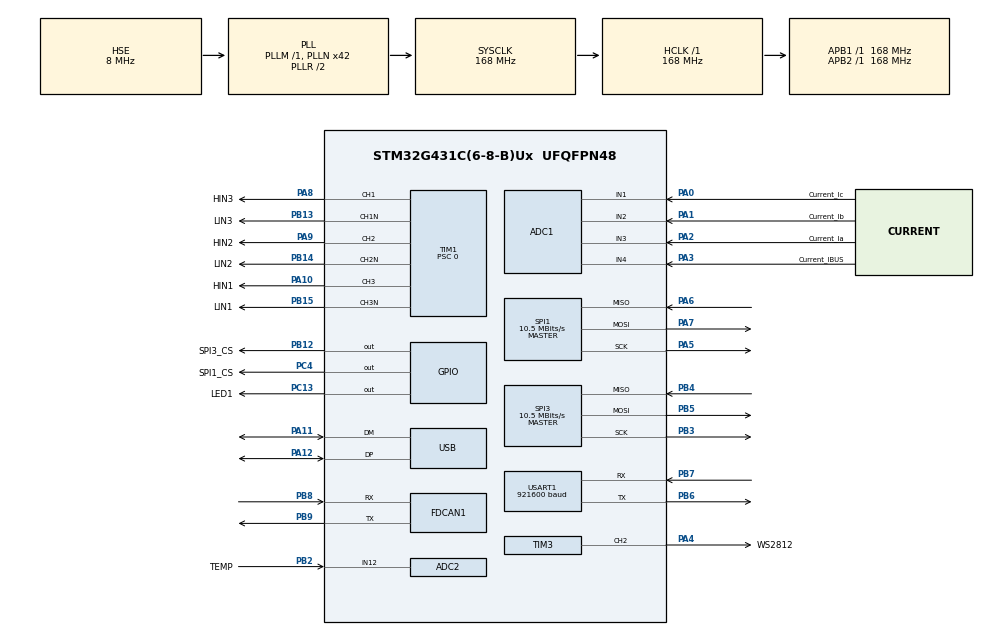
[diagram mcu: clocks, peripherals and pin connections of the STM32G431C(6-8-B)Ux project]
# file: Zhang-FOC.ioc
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ADC1.ClockPrescaler=ADC_CLOCK_SYNC_PCLK_DIV4
ADC1.ContinuousConvMode=DISABLE
ADC1.DMAContinuousRequests=DISABLE
ADC1.EOCSelection=ADC_EOC_SINGLE_CONV
ADC1.EnableAnalogWatchDog1=false
ADC1.EnableInjectedConversion=ENABLE
ADC1.EnableRegularConversion=DISABLE
ADC1.ExternalTrigInjecConv=ADC_EXTERNALTRIGINJEC_T1_CC4
ADC1.ExternalTrigInjecConvEdge=ADC_EXTERNALTRIGINJECCONV_EDGE_RISING
ADC1.InjNumberOfConversion=4
ADC1.InjectedChannel-4\#ChannelInjectedConversion=ADC_CHANNEL_1
ADC1.InjectedChannel-5\#ChannelInjectedConversion=ADC_CHANNEL_2
ADC1.InjectedChannel-6\#ChannelInjectedConversion=ADC_CHANNEL_3
ADC1.InjectedChannel-7\#ChannelInjectedConversion=ADC_CHANNEL_4
ADC1.InjectedOffsetNumber-4\#ChannelInjectedConversion=ADC_OFFSET_NONE
ADC1.InjectedOffsetNumber-5\#ChannelInjectedConversion=ADC_OFFSET_NONE
ADC1.InjectedOffsetNumber-6\#ChannelInjectedConversion=ADC_OFFSET_NONE
ADC1.InjectedOffsetNumber-7\#ChannelInjectedConversion=ADC_OFFSET_NONE
ADC1.InjectedRank-4\#ChannelInjectedConversion=1
ADC1.InjectedRank-5\#ChannelInjectedConversion=2
ADC1.InjectedRank-6\#ChannelInjectedConversion=3
ADC1.InjectedRank-7\#ChannelInjectedConversion=4
ADC1.InjectedSamplingTime-4\#ChannelInjectedConversion=ADC_SAMPLETIME_6CYCLES_5
ADC1.InjectedSamplingTime-5\#ChannelInjectedConversion=ADC_SAMPLETIME_6CYCLES_5
ADC1.InjectedSamplingTime-6\#ChannelInjectedConversion=ADC_SAMPLETIME_6CYCLES_5
ADC1.InjectedSamplingTime-7\#ChannelInjectedConversion=ADC_SAMPLETIME_6CYCLES_5
ADC1.master=1
ADC2.Channel-0\#ChannelRegularConversion=ADC_CHANNEL_12
ADC2.ContinuousConvMode=ENABLE
ADC2.DMAContinuousRequests=ENABLE
ADC2.GainCompensation=0
ADC2.NbrOfConversionFlag=1
ADC2.OffsetNumber-0\#ChannelRegularConversion=ADC_OFFSET_NONE
ADC2.Rank-0\#ChannelRegularConversion=1
ADC2.SamplingTime-0\#ChannelRegularConversion=ADC_SAMPLETIME_47CYCLES_5
Dma.ADC2.1.Direction=DMA_PERIPH_TO_MEMORY
Dma.ADC2.1.EventEnable=DISABLE
Dma.ADC2.1.Instance=DMA1_Channel2
Dma.ADC2.1.MemDataAlignment=DMA_MDATAALIGN_HALFWORD
Dma.ADC2.1.MemInc=DMA_MINC_ENABLE
Dma.ADC2.1.Mode=DMA_CIRCULAR
Dma.ADC2.1.PeriphDataAlignment=DMA_PDATAALIGN_HALFWORD
Dma.ADC2.1.PeriphInc=DMA_PINC_DISABLE
Dma.ADC2.1.Polarity=HAL_DMAMUX_REQ_GEN_RISING
Dma.ADC2.1.Priority=DMA_PRIORITY_MEDIUM
Dma.ADC2.1.RequestNumber=1
Dma.ADC2.1.SignalID=NONE
Dma.ADC2.1.SyncEnable=DISABLE
Dma.ADC2.1.SyncPolarity=HAL_DMAMUX_SYNC_NO_EVENT
Dma.ADC2.1.SyncRequestNumber=1
Dma.ADC2.1.SyncSignalID=NONE
Dma.Request0=TIM3_CH2
Dma.Request1=ADC2
Dma.Request2=USART1_RX
Dma.Request3=USART1_TX
Dma.TIM3_CH2.0.Direction=DMA_MEMORY_TO_PERIPH
Dma.TIM3_CH2.0.EventEnable=DISABLE
Dma.TIM3_CH2.0.Instance=DMA1_Channel1
Dma.TIM3_CH2.0.MemDataAlignment=DMA_MDATAALIGN_WORD
Dma.TIM3_CH2.0.MemInc=DMA_MINC_ENABLE
Dma.TIM3_CH2.0.Mode=DMA_NORMAL
Dma.TIM3_CH2.0.PeriphDataAlignment=DMA_PDATAALIGN_WORD
Dma.TIM3_CH2.0.PeriphInc=DMA_PINC_DISABLE
Dma.TIM3_CH2.0.Polarity=HAL_DMAMUX_REQ_GEN_RISING
Dma.TIM3_CH2.0.Priority=DMA_PRIORITY_MEDIUM
Dma.TIM3_CH2.0.RequestNumber=1
Dma.TIM3_CH2.0.SignalID=NONE
Dma.TIM3_CH2.0.SyncEnable=DISABLE
Dma.TIM3_CH2.0.SyncPolarity=HAL_DMAMUX_SYNC_NO_EVENT
Dma.TIM3_CH2.0.SyncRequestNumber=1
Dma.TIM3_CH2.0.SyncSignalID=NONE
Dma.USART1_RX.2.Direction=DMA_PERIPH_TO_MEMORY
Dma.USART1_RX.2.EventEnable=DISABLE
Dma.USART1_RX.2.Instance=DMA1_Channel3
Dma.USART1_RX.2.MemDataAlignment=DMA_MDATAALIGN_BYTE
Dma.USART1_RX.2.MemInc=DMA_MINC_ENABLE
Dma.USART1_RX.2.Mode=DMA_NORMAL
Dma.USART1_RX.2.PeriphDataAlignment=DMA_PDATAALIGN_BYTE
Dma.USART1_RX.2.PeriphInc=DMA_PINC_DISABLE
Dma.USART1_RX.2.Polarity=HAL_DMAMUX_REQ_GEN_RISING
Dma.USART1_RX.2.Priority=DMA_PRIORITY_HIGH
Dma.USART1_RX.2.RequestNumber=1
Dma.USART1_RX.2.SignalID=NONE
Dma.USART1_RX.2.SyncEnable=DISABLE
Dma.USART1_RX.2.SyncPolarity=HAL_DMAMUX_SYNC_NO_EVENT
Dma.USART1_RX.2.SyncRequestNumber=1
Dma.USART1_RX.2.SyncSignalID=NONE
Dma.USART1_TX.3.Direction=DMA_MEMORY_TO_PERIPH
Dma.USART1_TX.3.EventEnable=DISABLE
Dma.USART1_TX.3.Instance=DMA1_Channel4
Dma.USART1_TX.3.MemDataAlignment=DMA_MDATAALIGN_BYTE
Dma.USART1_TX.3.MemInc=DMA_MINC_ENABLE
Dma.USART1_TX.3.Mode=DMA_NORMAL
Dma.USART1_TX.3.PeriphDataAlignment=DMA_PDATAALIGN_BYTE
Dma.USART1_TX.3.PeriphInc=DMA_PINC_DISABLE
Dma.USART1_TX.3.Polarity=HAL_DMAMUX_REQ_GEN_RISING
Dma.USART1_TX.3.Priority=DMA_PRIORITY_HIGH
Dma.USART1_TX.3.RequestNumber=1
Dma.USART1_TX.3.SignalID=NONE
Dma.USART1_TX.3.SyncEnable=DISABLE
Dma.USART1_TX.3.SyncPolarity=HAL_DMAMUX_SYNC_NO_EVENT
Dma.USART1_TX.3.SyncRequestNumber=1
Dma.USART1_TX.3.SyncSignalID=NONE
FDCAN1.AutoRetransmission=ENABLE
FDCAN1.CalculateBaudRateNominal=1000000
FDCAN1.CalculateTimeBitNominal=1000
FDCAN1.CalculateTimeQuantumNominal=35.714285714285715
FDCAN1.ClockDivider=FDCAN_CLOCK_DIV1
FDCAN1.DataPrescaler=6
FDCAN1.DataSyncJumpWidth=7
FDCAN1.DataTimeSeg1=20
FDCAN1.DataTimeSeg2=7
FDCAN1.NominalPrescaler=6
FDCAN1.NominalSyncJumpWidth=7
FDCAN1.NominalTimeSeg1=20
FDCAN1.NominalTimeSeg2=7
FDCAN1.ProtocolException=ENABLE
FDCAN1.StdFiltersNbr=1
FREERTOS.INCLUDE_uxTaskGetStackHighWaterMark=1
FREERTOS.INCLUDE_vTaskDelayUntil=1
FREERTOS.MEMORY_ALLOCATION=2
FREERTOS.Tasks01=defaultTask,0,128,StartDefaultTask,As weak,NULL,Dynamic,NULL,NULL;guardtask,0,128,StartGuardTask,As weak,NULL,Dynamic,NULL,NULL;customtask,1,400,StartCustomTask,As weak,NULL,Dynamic,NULL,NULL
FREERTOS.configCHECK_FOR_STACK_OVERFLOW=1
FREERTOS.configTOTAL_HEAP_SIZE=3000
FREERTOS.configUSE_APPLICATION_TASK_TAG=0
FREERTOS.configUSE_IDLE_HOOK=1
Mcu.Family=STM32G4
Mcu.Name=STM32G431C(6-8-B)Ux
Mcu.Package=UFQFPN48
Mcu.UserConstants=MCPWM_CLOCK_HZ,168000000;MCPWM_DEADTIME_CLOCKS,20;MCPWM_TGRO_TIME,MCPWM_PERIOD_CLOCKS-10;MCPWM_RCR,0;MCPWM_FREQ,20000;MCPWM_PERIOD_CLOCKS,MCPWM_CLOCK_HZ/2/MCPWM_FREQ
NVIC.ADC1_2_IRQn=true\:5\:0\:true\:false\:true\:true\:true\:true\:true
NVIC.DMA1_Channel1_IRQn=true\:5\:0\:false\:false\:true\:true\:false\:true\:true
NVIC.DMA1_Channel2_IRQn=true\:5\:0\:false\:false\:true\:true\:false\:true\:true
NVIC.DMA1_Channel3_IRQn=true\:5\:0\:false\:false\:true\:true\:false\:true\:true
NVIC.DMA1_Channel4_IRQn=true\:5\:0\:false\:false\:true\:true\:false\:true\:true
NVIC.FDCAN1_IT0_IRQn=true\:6\:0\:true\:false\:true\:true\:true\:true\:true
NVIC.FDCAN1_IT1_IRQn=true\:6\:0\:true\:false\:true\:true\:true\:true\:true
NVIC.PriorityGroup=NVIC_PRIORITYGROUP_4
NVIC.TIM1_TRG_COM_TIM17_IRQn=true\:15\:0\:false\:false\:true\:false\:false\:true\:true
NVIC.TimeBase=TIM1_TRG_COM_TIM17_IRQn
NVIC.TimeBaseIP=TIM17
NVIC.USART1_IRQn=true\:7\:0\:true\:false\:true\:true\:true\:true\:true
NVIC.USB_LP_IRQn=true\:5\:0\:false\:false\:true\:true\:false\:true\:true
PA0.GPIO_Label=Current_Ic
PA0.Mode=IN1-Single-Ended
PA0.Signal=ADC1_IN1
PA1.GPIO_Label=Current_Ib
PA1.Mode=IN2-Single-Ended
PA1.Signal=ADC1_IN2
PA10.GPIO_Label=HIN1
PA10.GPIO_Speed=GPIO_SPEED_FREQ_VERY_HIGH
PA10.Signal=S_TIM1_CH3
PA11.Mode=Device
PA11.Signal=USB_DM
PA12.Mode=Device
PA12.Signal=USB_DP
PA13.Mode=Serial_Wire
PA13.Signal=SYS_JTMS-SWDIO
PA14.Mode=Serial_Wire
PA14.Signal=SYS_JTCK-SWCLK
PA2.GPIO_Label=Current_Ia
PA2.Mode=IN3-Single-Ended
PA2.Signal=ADC1_IN3
PA3.GPIO_Label=Current_IBUS
PA3.Mode=IN4-Single-Ended
PA3.Signal=ADC1_IN4
PA4.GPIO_Label=WS2812
PA4.Signal=S_TIM3_CH2
PA5.GPIO_Speed=GPIO_SPEED_FREQ_VERY_HIGH
PA5.Mode=Full_Duplex_Master
PA5.Signal=SPI1_SCK
PA6.GPIO_Speed=GPIO_SPEED_FREQ_VERY_HIGH
PA6.Mode=Full_Duplex_Master
PA6.Signal=SPI1_MISO
PA7.GPIO_Speed=GPIO_SPEED_FREQ_VERY_HIGH
PA7.Mode=Full_Duplex_Master
PA7.Signal=SPI1_MOSI
PA8.GPIO_Label=HIN3
PA8.GPIO_Speed=GPIO_SPEED_FREQ_VERY_HIGH
PA8.Signal=S_TIM1_CH1
PA9.GPIO_Label=HIN2
PA9.GPIO_Speed=GPIO_SPEED_FREQ_VERY_HIGH
PA9.Signal=S_TIM1_CH2
PB12.GPIO_Label=SPI3_CS
PB12.GPIO_Speed=GPIO_SPEED_FREQ_VERY_HIGH
PB12.Signal=GPIO_Output
PB13.GPIO_Label=LIN3
PB13.GPIO_Speed=GPIO_SPEED_FREQ_VERY_HIGH
PB13.Mode=PWM Generation1 CH1 CH1N
PB13.Signal=TIM1_CH1N
PB14.GPIO_Label=LIN2
PB14.GPIO_Speed=GPIO_SPEED_FREQ_VERY_HIGH
PB14.Mode=PWM Generation2 CH2 CH2N
PB14.Signal=TIM1_CH2N
PB15.GPIO_Label=LIN1
PB15.GPIO_Speed=GPIO_SPEED_FREQ_VERY_HIGH
PB15.Mode=PWM Generation3 CH3 CH3N
PB15.Signal=TIM1_CH3N
PB2.GPIO_Label=TEMP
PB2.Mode=IN12-Single-Ended
PB2.Signal=ADC2_IN12
PB3.GPIO_Speed=GPIO_SPEED_FREQ_VERY_HIGH
PB3.Mode=Full_Duplex_Master
PB3.Signal=SPI3_SCK
PB4.GPIO_Speed=GPIO_SPEED_FREQ_VERY_HIGH
PB4.Mode=Full_Duplex_Master
PB4.Signal=SPI3_MISO
PB5.GPIO_Speed=GPIO_SPEED_FREQ_VERY_HIGH
PB5.Mode=Full_Duplex_Master
PB5.Signal=SPI3_MOSI
PB6.GPIO_Speed=GPIO_SPEED_FREQ_VERY_HIGH
PB6.Mode=Asynchronous
PB6.Signal=USART1_TX
PB7.GPIO_Speed=GPIO_SPEED_FREQ_VERY_HIGH
PB7.Mode=Asynchronous
PB7.Signal=USART1_RX
PB8-BOOT0.GPIO_Speed=GPIO_SPEED_FREQ_VERY_HIGH
PB8-BOOT0.Mode=FDCAN_Activate
PB8-BOOT0.Signal=FDCAN1_RX
PB9.GPIO_Speed=GPIO_SPEED_FREQ_VERY_HIGH
PB9.Mode=FDCAN_Activate
PB9.Signal=FDCAN1_TX
PC13.GPIO_Label=LED1
PC13.Signal=GPIO_Output
PC4.GPIO_Label=SPI1_CS
PC4.GPIO_Speed=GPIO_SPEED_FREQ_VERY_HIGH
PC4.Signal=GPIO_Output
PF0-OSC_IN.Mode=HSE-External-Oscillator
PF0-OSC_IN.Signal=RCC_OSC_IN
PF1-OSC_OUT.Mode=HSE-External-Oscillator
PF1-OSC_OUT.Signal=RCC_OSC_OUT
ProjectManager.HeapSize=0x3000
ProjectManager.StackSize=0x1000
ProjectManager.TargetToolchain=MDK-ARM V5.32
RCC.ADC12CLockSelection=RCC_ADC12CLKSOURCE_PLL
RCC.ADC12Freq_Value=168000000
RCC.AHBFreq_Value=168000000
RCC.APB1Freq_Value=168000000
RCC.APB1TimFreq_Value=168000000
RCC.APB2Freq_Value=168000000
RCC.APB2TimFreq_Value=168000000
RCC.CK48CLockSelection=RCC_USBCLKSOURCE_HSI48
RCC.CortexFreq_Value=168000000
RCC.EXTERNAL_CLOCK_VALUE=12288000
RCC.FDCANCLockSelection=RCC_FDCANCLKSOURCE_PLL
RCC.HCLKFreq_Value=168000000
RCC.HSE_VALUE=8000000
RCC.HSI48_VALUE=48000000
RCC.HSI_VALUE=16000000
RCC.LSE_VALUE=32768
RCC.PLLN=42
RCC.PLLSourceVirtual=RCC_PLLSOURCE_HSE
RCC.SYSCLKFreq_VALUE=168000000
RCC.SYSCLKSource=RCC_SYSCLKSOURCE_PLLCLK
RCC.USBFreq_Value=48000000
RCC.VCOOutputFreq_Value=336000000
SH.S_TIM1_CH1.0=TIM1_CH1,PWM Generation1 CH1 CH1N
SH.S_TIM1_CH2.0=TIM1_CH2,PWM Generation2 CH2 CH2N
SH.S_TIM1_CH3.0=TIM1_CH3,PWM Generation3 CH3 CH3N
SH.S_TIM3_CH2.0=TIM3_CH2,PWM Generation2 CH2
SPI1.BaudRatePrescaler=SPI_BAUDRATEPRESCALER_16
SPI1.CLKPhase=SPI_PHASE_2EDGE
SPI1.CLKPolarity=SPI_POLARITY_HIGH
SPI1.CalculateBaudRate=10.5 MBits/s
SPI1.DataSize=SPI_DATASIZE_8BIT
SPI1.Direction=SPI_DIRECTION_2LINES
SPI1.Mode=SPI_MODE_MASTER
SPI1.VirtualType=VM_MASTER
SPI3.BaudRatePrescaler=SPI_BAUDRATEPRESCALER_16
SPI3.CLKPhase=SPI_PHASE_2EDGE
SPI3.CLKPolarity=SPI_POLARITY_HIGH
SPI3.CalculateBaudRate=10.5 MBits/s
SPI3.DataSize=SPI_DATASIZE_8BIT
SPI3.Direction=SPI_DIRECTION_2LINES
SPI3.Mode=SPI_MODE_MASTER
SPI3.VirtualType=VM_MASTER
STMicroelectronics.X-CUBE-ALGOBUILD.1.4.0.LibraryCcDSPOoLibraryJjDSPOoLibrary=true
TIM1.BreakFilter=0
TIM1.BreakState=TIM_BREAK_DISABLE
TIM1.Channel-PWM\ Generation1\ CH1\ CH1N=TIM_CHANNEL_1
TIM1.Channel-PWM\ Generation2\ CH2\ CH2N=TIM_CHANNEL_2
TIM1.Channel-PWM\ Generation3\ CH3\ CH3N=TIM_CHANNEL_3
TIM1.Channel-PWM\ Generation4\ No\ Output=TIM_CHANNEL_4
TIM1.ClockDivision=TIM_CLOCKDIVISION_DIV1
TIM1.CounterMode=TIM_COUNTERMODE_CENTERALIGNED1
TIM1.DeadTime=MCPWM_DEADTIME_CLOCKS
TIM1.LockLevel=TIM_LOCKLEVEL_OFF
TIM1.OCMode_PWM-PWM\ Generation4\ No\ Output=TIM_OCMODE_PWM1
TIM1.OCNPolarity_1=TIM_OCNPOLARITY_HIGH
TIM1.OffStateIDLEMode=TIM_OSSI_DISABLE
TIM1.OffStateRunMode=TIM_OSSR_DISABLE
TIM1.PeriodNoDither=MCPWM_PERIOD_CLOCKS
TIM1.Prescaler=0
TIM1.PulseNoDither_4=MCPWM_TGRO_TIME
TIM1.RepetitionCounter=MCPWM_RCR
TIM1.TIM_MasterOutputTrigger=TIM_TRGO_OC4REF
TIM1.TIM_MasterOutputTrigger2=TIM_TRGO2_RESET
TIM3.Channel-PWM\ Generation2\ CH2=TIM_CHANNEL_2
TIM3.PeriodNoDither=210-1
TIM3.Prescaler=0
USART1.BaudRate=921600
USART1.VirtualMode-Asynchronous=VM_ASYNC
USB_DEVICE.CLASS_NAME_FS=CDC
USB_DEVICE.VirtualMode=Cdc
USB_DEVICE.VirtualModeFS=Cdc_FS
VP_CRC_VS_CRC.Mode=CRC_Activate
VP_FREERTOS_VS_CMSIS_V1.Mode=CMSIS_V1
VP_RNG_VS_RNG.Mode=RNG_Activate
VP_STMicroelectronics.X-CUBE-ALGOBUILD_VS_DSPOoLibraryJjLibrary_1.4.0_1.4.0.Mode=DSPOoLibraryJjLibrary
VP_SYS_VS_DBSignals.Mode=DisableDeadBatterySignals
VP_SYS_VS_tim17.Mode=TIM17
VP_TIM1_VS_no_output4.Mode=PWM Generation4 No Output
VP_USB_DEVICE_VS_USB_DEVICE_CDC_FS.Mode=CDC_FS
board=custom

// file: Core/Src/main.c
/* USER CODE BEGIN Header */
/**
 ******************************************************************************
 * @file           : main.c
 * @brief          : Main program body
 ******************************************************************************
 * @attention
 *
 * Copyright (c) 2024 STMicroelectronics.
 * All rights reserved.
 *
 * This software is licensed under terms that can be found in the LICENSE file
 * in the root directory of this software component.
 * If no LICENSE file comes with this software, it is provided AS-IS.
 *
 ******************************************************************************
 */
/* USER CODE END Header */
#include "main.h"
#include "cmsis_os.h"
#include "adc.h"
#include "crc.h"
#include "dma.h"
#include "fdcan.h"
#include "rng.h"
#include "spi.h"
#include "tim.h"
#include "usart.h"
#include "usb_device.h"
#include "gpio.h"

/* USER CODE BEGIN Includes */
#include "robot.h"
/* USER CODE END Includes */

void SystemClock_Config(void);
void MX_FREERTOS_Init(void);

int main(void)
{

  /* MCU Configuration--------------------------------------------------------*/

  /* Reset of all peripherals, Initializes the Flash interface and the Systick. */
  HAL_Init();

  /* Configure the system clock */
  SystemClock_Config();

  /* Initialize all configured peripherals */
  MX_GPIO_Init();
  MX_DMA_Init();
  MX_ADC1_Init();
  MX_FDCAN1_Init();
  MX_SPI1_Init();
  MX_TIM3_Init();
  MX_TIM1_Init();
  MX_ADC2_Init();
  MX_SPI3_Init();
  MX_USART1_UART_Init();
  MX_CRC_Init();
  MX_RNG_Init();
  /* USER CODE BEGIN 2 */
  // RGB_DisplayColorById(4);
  RobotInit();
  /* USER CODE END 2 */

  /* Call init function for freertos objects (in cmsis_os2.c) */
  MX_FREERTOS_Init();

  /* Start scheduler */
  osKernelStart();

  /* We should never get here as control is now taken by the scheduler */

  /* Infinite loop */
  while (1)
  {

    /* USER CODE BEGIN 3 */

    //    vofa_start();
  }
  /* USER CODE END 3 */
}

void SystemClock_Config(void)
{
  RCC_OscInitTypeDef RCC_OscInitStruct = {0};
  RCC_ClkInitTypeDef RCC_ClkInitStruct = {0};

  /** Configure the main internal regulator output voltage
  */
  HAL_PWREx_ControlVoltageScaling(PWR_REGULATOR_VOLTAGE_SCALE1_BOOST);

  /** Initializes the RCC Oscillators according to the specified parameters
  * in the RCC_OscInitTypeDef structure.
  */
  RCC_OscInitStruct.OscillatorType = RCC_OSCILLATORTYPE_HSI48|RCC_OSCILLATORTYPE_HSE;
  RCC_OscInitStruct.HSEState = RCC_HSE_ON;
  RCC_OscInitStruct.HSI48State = RCC_HSI48_ON;
  RCC_OscInitStruct.PLL.PLLState = RCC_PLL_ON;
  RCC_OscInitStruct.PLL.PLLSource = RCC_PLLSOURCE_HSE;
  RCC_OscInitStruct.PLL.PLLM = RCC_PLLM_DIV1;
  RCC_OscInitStruct.PLL.PLLN = 42;
  RCC_OscInitStruct.PLL.PLLP = RCC_PLLP_DIV2;
  RCC_OscInitStruct.PLL.PLLQ = RCC_PLLQ_DIV2;
  RCC_OscInitStruct.PLL.PLLR = RCC_PLLR_DIV2;
  if (HAL_RCC_OscConfig(&RCC_OscInitStruct) != HAL_OK)
  {
    Error_Handler();
  }

  /** Initializes the CPU, AHB and APB buses clocks
  */
  RCC_ClkInitStruct.ClockType = RCC_CLOCKTYPE_HCLK|RCC_CLOCKTYPE_SYSCLK
                              |RCC_CLOCKTYPE_PCLK1|RCC_CLOCKTYPE_PCLK2;
  RCC_ClkInitStruct.SYSCLKSource = RCC_SYSCLKSOURCE_PLLCLK;
  RCC_ClkInitStruct.AHBCLKDivider = RCC_SYSCLK_DIV1;
  RCC_ClkInitStruct.APB1CLKDivider = RCC_HCLK_DIV1;
  RCC_ClkInitStruct.APB2CLKDivider = RCC_HCLK_DIV1;

  if (HAL_RCC_ClockConfig(&RCC_ClkInitStruct, FLASH_LATENCY_4) != HAL_OK)
  {
    Error_Handler();
  }
}

void HAL_TIM_PeriodElapsedCallback(TIM_HandleTypeDef *htim)
{
  if (htim->Instance == TIM17)
  {
    HAL_IncTick();
  }
}

void Error_Handler(void)
{
  __disable_irq();
  while (1)
  {
  }
}
